# RTS5918 register map
Vendor: Realtek Semiconductor Corp.; Series: RTS5918 Series; File version: 1.00
CPU: ARMV8MML r0p0, little endian, MPU, FPU, VTOR, 3 interrupt priority bits, 8 SAU regions
Registers are 32-bit, read-write, reset 0x0 unless marked. A register's access mark holds for its fields unless they carry their own. Offsets are from the block's base; [hi:lo] are bit positions; {n}, {i} and the like mark numbered series.

## DIO0 — Dedicated I/O Controller
Base 0x400A02C0
Same registers: DIO1 0x400A02C8
0x00 BASEADDR — BASE ADDRESS REGISTER
  [15:0] ADDR — Base address
0x04 ENABLE — DIO ENABLE REGISTER
  [0] EN — Dedicated I/O Activate
    0=DISABLE (Disable DIO); 1=ENABLE (Enable DIO)

## PORT80 — PORT80 Controller
Base 0x40221200
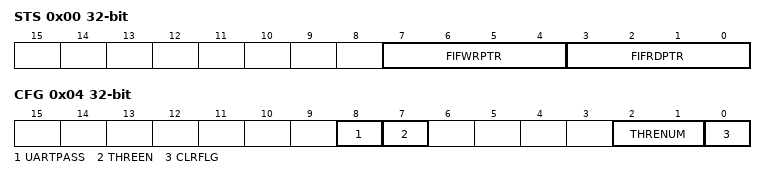
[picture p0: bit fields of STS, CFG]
0x00 STS ro — STATUS REGISTER
  [7:4] FIFWRPTR — FIFO Read Pointer
  [3:0] FIFRDPTR — FIFO Read Pointer
0x04 CFG — CONFIGURATION REGISTER
  [8] UARTPASS — Enable Port80 Decode to UART
    0=DISABLE (Disable port80 decode to UART); 1=ENABLE (Enable port80 decode to UART)
  [7] THREEN — Enable Threshold
    0=DISABLE (Disable threshold); 1=ENABLE (Enable threshold)
  [2:1] THRENUM — FIFO Threshold
    0=x1 entry threshold; 1=x4 (x4 entry threshold); 2=x8 (x8 entry threshold); 3=x12 (x12 entry threshold)
  [0] CLRFLG write-1-clears — Clear Flag
    0=DO_NOTHING; 1=CLEAR (Clear flag)
0x08 INTEN — INTERRUPT ENABLE REGISTER
  [0] THREINTEN — Enable Threshold Interrupt
    0=DISABLE (Disabled threshold interrupt); 1=ENABLE (Enable threshold interrupt)
0x0C DATA
0x10 ADDR — ADDRESS REGISTER
  [7:0] ADDR — Address

## MONOTONIC — Monotonic Counter
Base 0x400B1400
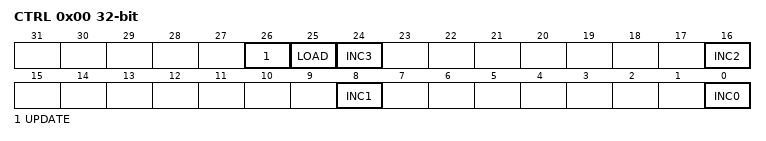
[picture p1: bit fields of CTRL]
0x00 CTRL — CONTROL REGISTER
  [26] UPDATE — Update monotonic counter #0 to #3 from VBAT domain
  [25] LOAD — Load monotonic counter #0 to #3 to VBAT domain
  [8n] INC{n} (n=0..3) — Increase monotonic counter #{n} by 1
{0x4+4i} MCNT{i} (i=0..3) — MONOTONIC COUNTER #{i} REGISTER

## MBX — Mailbox Controller
Base 0x400B1600
0x00 STS — MAILBOX STATUS REGISTER
  [7:0] STS — Status
{0x4+4i} DATA[{i}] (i=0..47) — MAILBOX DATA{i} REGISTER
  [7:0] DATA — Mailbox Data Buffer
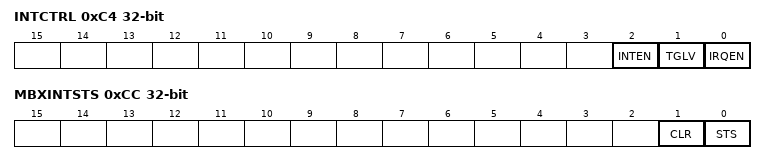
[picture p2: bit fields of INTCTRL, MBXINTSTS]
0xC4 INTCTRL — MAILBOX INTERRUPT CONTROL REGISTER
  [2] INTEN — Interrupt Enable
    0=DISABLE (Disable interrupt); 1=ENABLE (Enable interrupt)
  [1] TGLV — Trigger Level Select
    0=LOW (Low level trigger select); 1=HIGH (High level trigger select)
  [0] IRQEN — Auto IRQ Enable
    0=DISABLE (Disabled auto IRQ); 1=ENABLE (Enable auto IRQ)
0xC8 MBXIRQNUM — MAILBOX IRQ NUMBER REGISTER
  [7:0] NUM — IRQ Number
0xCC MBXINTSTS — MAILBOX INTERRUPT STATUS REGISTER
  [1] CLR — Write 1 to clear interrupt status
  [0] STS write-1-clears — Indicate wheather the interrupt is occurred
    0=NOT_OCCURRED (Interrupt is not occurred); 1=OCCURRED (Interrupt is occurred)

## LEDSTP — LED Strip Controller
Base 0x40251A00
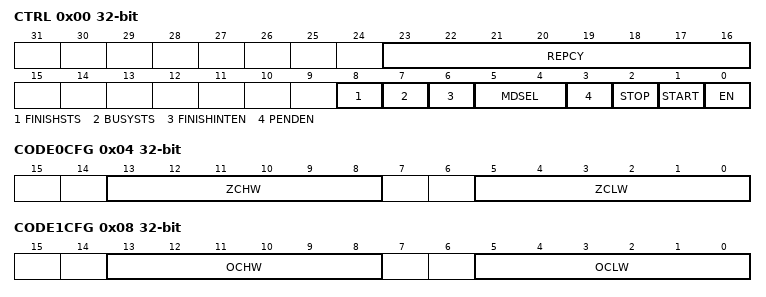
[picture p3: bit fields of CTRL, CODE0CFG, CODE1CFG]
0x00 CTRL — LEDSTP CONFIGURATION REGISTER
  [23:16] REPCY — LED Strip Repeat Cycle
  [8] FINISHSTS — LED Strip Transfer Finish
    0=IDLE (No Action); 1=CLEAR (Clear Transfer Finish Flag)
  [7] BUSYSTS — LED Strip Busy Status
    0=NONE (No Action); 1=CLEAR (Clear Busy Deasserted Flag)
  [6] FINISHINTEN — LED Strip Finish Interrupt Enable
    0=DISABLE (Disable LED Strip Done Interrupt); 1=ENABLE (Enable LED Strip Done Interrupt)
  [5:4] MDSEL — LED Strip Mode Selection
    0=ONESHOT (One shot Mode); 1=REPEAT (Repeat Mode); 2=ALWAYS (Always Run Mode)
  [3] PENDEN — LED Strip Pending Code Enable
    0=DISABLE (Disable Pending Code); 1=ENABLE (Enable Pending Code)
  [2] STOP — STOP LED Strip
    0=NONE (No Action); 1=STOP (STOP LED Strip)
  [1] START — START LED Strip
    0=NONE (No Action); 1=START (START LED Strip)
  [0] EN — Enable LED Strip
    0=DISBLE (Disable LED Strip); 1=ENABLE (Enable LED Strip)
0x04 CODE0CFG — LEDSTP 0 CODE PERIOD REGISTER
  [13:8] ZCHW — LED Strip 0 Code High Width
  [5:0] ZCLW — LED Strip 0 Code Low Width
0x08 CODE1CFG — LEDSTP 1 CODE PERIOD REGISTER
  [13:8] OCHW — LED Strip 1 High Width
  [5:0] OCLW — LED Strip 1 Low Width
0x0C RSTCFG — LEDSTP RESET TIME REGISTER
  [31:0] RSTW — LED Strip Reset Time
0x10 PCFG — LEDSTP PENDING TIME REGISTER
  [5:0] PENDW — LED Strip Pending Time (ms)
0x14 TRANSADD — LEDSTP PATTERN ADDRESS REGISTER
0x18 TRANSLEN — LEDSTP TRANSFER LENGTH REGISTER
  [13:0] TRANSLEN — LED Strip Transfer Length (Bytes)
